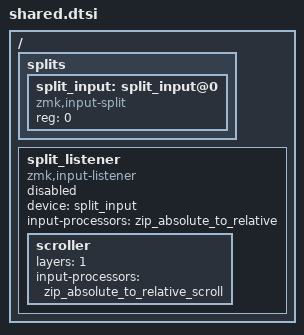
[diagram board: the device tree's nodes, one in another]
/*
 * Copyright (c) 2026 amgskobo
 * SPDX-License-Identifier: MIT
 *
 * What both halves share: the peripheral's input device reaches the central
 * through a ZMK input split, whose central side the listener reads. Layer 1
 * routes it through a second converter that also suppresses BTN_0.
 */

#include <behaviors/input_processor_absolute_to_relative.dtsi>

/ {
    splits {
        #address-cells = <1>;
        #size-cells = <0>;

        split_input: split_input@0 {
            compatible = "zmk,input-split";
            reg = <0>;
        };
    };

    split_listener: split_listener {
        compatible = "zmk,input-listener";
        status = "disabled";
        device = <&split_input>;
        input-processors = <&zip_absolute_to_relative>;

        scroller {
            layers = <1>;
            input-processors = <&zip_absolute_to_relative_scroll>;
        };
    };
};
